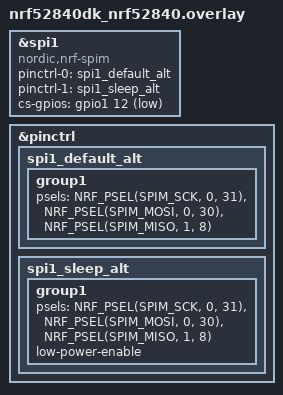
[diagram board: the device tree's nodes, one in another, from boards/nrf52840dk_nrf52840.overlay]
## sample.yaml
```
sample:
  name: spi master
tests:
  sample.boards.nrf.nrfx:
    platform_allow: nrf52840dk_nrf52840 nrf9160dk_nrf9160_ns nrf5340dk_nrf5340_cpuapp
    tags: board
    harness: console
```

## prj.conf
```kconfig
#
# Copyright (c) 2018 Nordic Semiconductor
#
# SPDX-License-Identifier: LicenseRef-Nordic-5-Clause
#

# Enable DK LED and Buttons library
CONFIG_DK_LIBRARY=y

# This example requires more workqueue stack
CONFIG_SYSTEM_WORKQUEUE_STACK_SIZE=2048

# Config logger
CONFIG_LOG=y
CONFIG_LOG_PRINTK=y

CONFIG_SPI=y
CONFIG_NRFX_SPIM1=y
```

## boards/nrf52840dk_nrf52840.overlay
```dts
/* overlay file */

my_spi: &spi1 {
	status = "okay"; 
	compatible = "nordic,nrf-spim";
	pinctrl-0 = <&spi1_default_alt>;
	pinctrl-1 = <&spi1_sleep_alt>;
	pinctrl-names = "default", "sleep";	
	cs-gpios = <&gpio1 12 GPIO_ACTIVE_LOW>;
};

&pinctrl {

	spi1_default_alt: spi1_default_alt {
		group1 {
			psels = <NRF_PSEL(SPIM_SCK, 0, 31)>,
				<NRF_PSEL(SPIM_MOSI, 0, 30)>,
				<NRF_PSEL(SPIM_MISO, 1, 8)>;
		};
	};

	spi1_sleep_alt: spi1_sleep_alt {
		group1 {
			psels = <NRF_PSEL(SPIM_SCK, 0, 31)>,
				<NRF_PSEL(SPIM_MOSI, 0, 30)>,
				<NRF_PSEL(SPIM_MISO, 1, 8)>;
			low-power-enable;
		};
	};

};
```

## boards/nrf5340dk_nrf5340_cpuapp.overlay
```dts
/* overlay file */

my_spi: &spi1 {
	status = "okay"; 
	compatible = "nordic,nrf-spim";
	sck-pin = < 47 >;
	miso-pin = < 46 >;
	mosi-pin = < 45 >;
	cs-gpios = <&gpio1 12 GPIO_ACTIVE_LOW>;
};
```

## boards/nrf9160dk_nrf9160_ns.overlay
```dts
/* overlay file */

my_spi: &spi1 {
	status = "okay"; 
	compatible = "nordic,nrf-spim";
	pinctrl-0 = <&spi1_default_alt>;
	pinctrl-1 = <&spi1_sleep_alt>;
	pinctrl-names = "default", "sleep";	
	cs-gpios = <&gpio0 6 GPIO_ACTIVE_LOW>;
};

&pinctrl {

	spi1_default_alt: spi1_default_alt {
		group1 {
			psels = <NRF_PSEL(SPIM_SCK, 0, 7)>,
				<NRF_PSEL(SPIM_MOSI, 0, 8)>,
				<NRF_PSEL(SPIM_MISO, 0, 9)>;
			nordic,drive-mode = <NRF_DRIVE_H0H1>;		
		};
	};

	spi1_sleep_alt: spi1_sleep_alt {
		group1 {
			psels = <NRF_PSEL(SPIM_SCK, 0, 7)>,
				<NRF_PSEL(SPIM_MOSI, 0, 8)>,
				<NRF_PSEL(SPIM_MISO, 0, 9)>;
			low-power-enable;
		};
	};

};
```

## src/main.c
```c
/*
 * Copyright (c) 2020 Nordic Semiconductor ASA
 *
 * SPDX-License-Identifier: LicenseRef-BSD-5-Clause-Nordic
 */

#include <zephyr/kernel.h>
#include <zephyr/device.h>
#include <zephyr/devicetree.h>
#include <zephyr/drivers/gpio.h>
#include <zephyr/logging/log.h>
#include <zephyr/drivers/spi.h>

#define LOG_MODULE_NAME spi_thread
LOG_MODULE_REGISTER(LOG_MODULE_NAME);

#define DELAY_SPI_CS_ACTIVE_US 2
#define TEST_STRING "Nordic"

const struct device *spi_dev;

static int spi_data_exchange(void)
{
    int err;
    struct spi_cs_control cs_ctrl;
    struct spi_config spi_cfg = {0};

	spi_cfg.frequency = 8000000U;
	spi_cfg.operation = SPI_WORD_SET(8);	

	// cs_ctrl.gpio_dev = device_get_binding(DT_SPI_DEV_CS_GPIOS_LABEL(DT_NODELABEL(spi_sensor)));
	cs_ctrl.gpio.port = DEVICE_DT_GET(DT_GPIO_CTLR(DT_NODELABEL(my_spi), cs_gpios));
	
	if (!cs_ctrl.gpio.port) {
        LOG_ERR("cannot find CS GPIO device");
		return -ENODEV;
	}

	// cs_ctrl.gpio_pin = DT_SPI_DEV_CS_GPIOS_PIN(DT_NODELABEL(spi_sensor));
	// cs_ctrl.gpio_dt_flags = DT_SPI_DEV_CS_GPIOS_FLAGS(DT_NODELABEL(spi_sensor));

	cs_ctrl.gpio.pin = DT_GPIO_PIN(DT_NODELABEL(my_spi), cs_gpios);
	cs_ctrl.gpio.dt_flags = DT_GPIO_FLAGS(DT_NODELABEL(my_spi), cs_gpios);

	cs_ctrl.delay = DELAY_SPI_CS_ACTIVE_US;

	spi_cfg.cs = &cs_ctrl;

	uint8_t buf[] = TEST_STRING;
    uint8_t data[] = TEST_STRING;

	struct spi_buf spi_buf[2] = {
		{
			.buf = buf,
			.len = sizeof(buf),
		},
		{
			.buf = data,
			.len = sizeof(data)
		}
	};
    
	const struct spi_buf_set tx_set = {
		.buffers = spi_buf,
		.count = 1
	};

	const struct spi_buf_set rx_set = {
		.buffers = spi_buf,
		.count = 1
	};

	// const struct spi_buf_set tx_set = {
	// 	.buffers = spi_buf,
	// 	.count = 2
	// };

	// const struct spi_buf_set rx_set = {
	// 	.buffers = spi_buf,
	// 	.count = 2
	// };    

	err = spi_transceive(spi_dev, &spi_cfg, &tx_set, &rx_set);
    
    if (err)
    {
        LOG_ERR("SPI transcation failed err %d", err);
    }
    else
    {
        LOG_HEXDUMP_INF(rx_set.buffers->buf, rx_set.buffers->len, "Received SPI data: ");
    }

    return err;

}

void main(void)
{	
	
	LOG_INF("** SPI master example **");
	LOG_INF("This example is ported from nRF5_SDK\\examples\\peripheral\\spi");
	LOG_INF("The related spis example is from nRF5_SDK\\examples\\peripheral\\spis");
	
	spi_dev = device_get_binding(DT_NODE_FULL_NAME(DT_NODELABEL(my_spi)));
	if (!spi_dev) {
		LOG_ERR("SPIM driver not found.\n");
		return;
	}
    
	while (1) {                
        LOG_INF("spi master thread");
        spi_data_exchange();
        k_sleep(K_SECONDS(2)); 
	}
}
```
